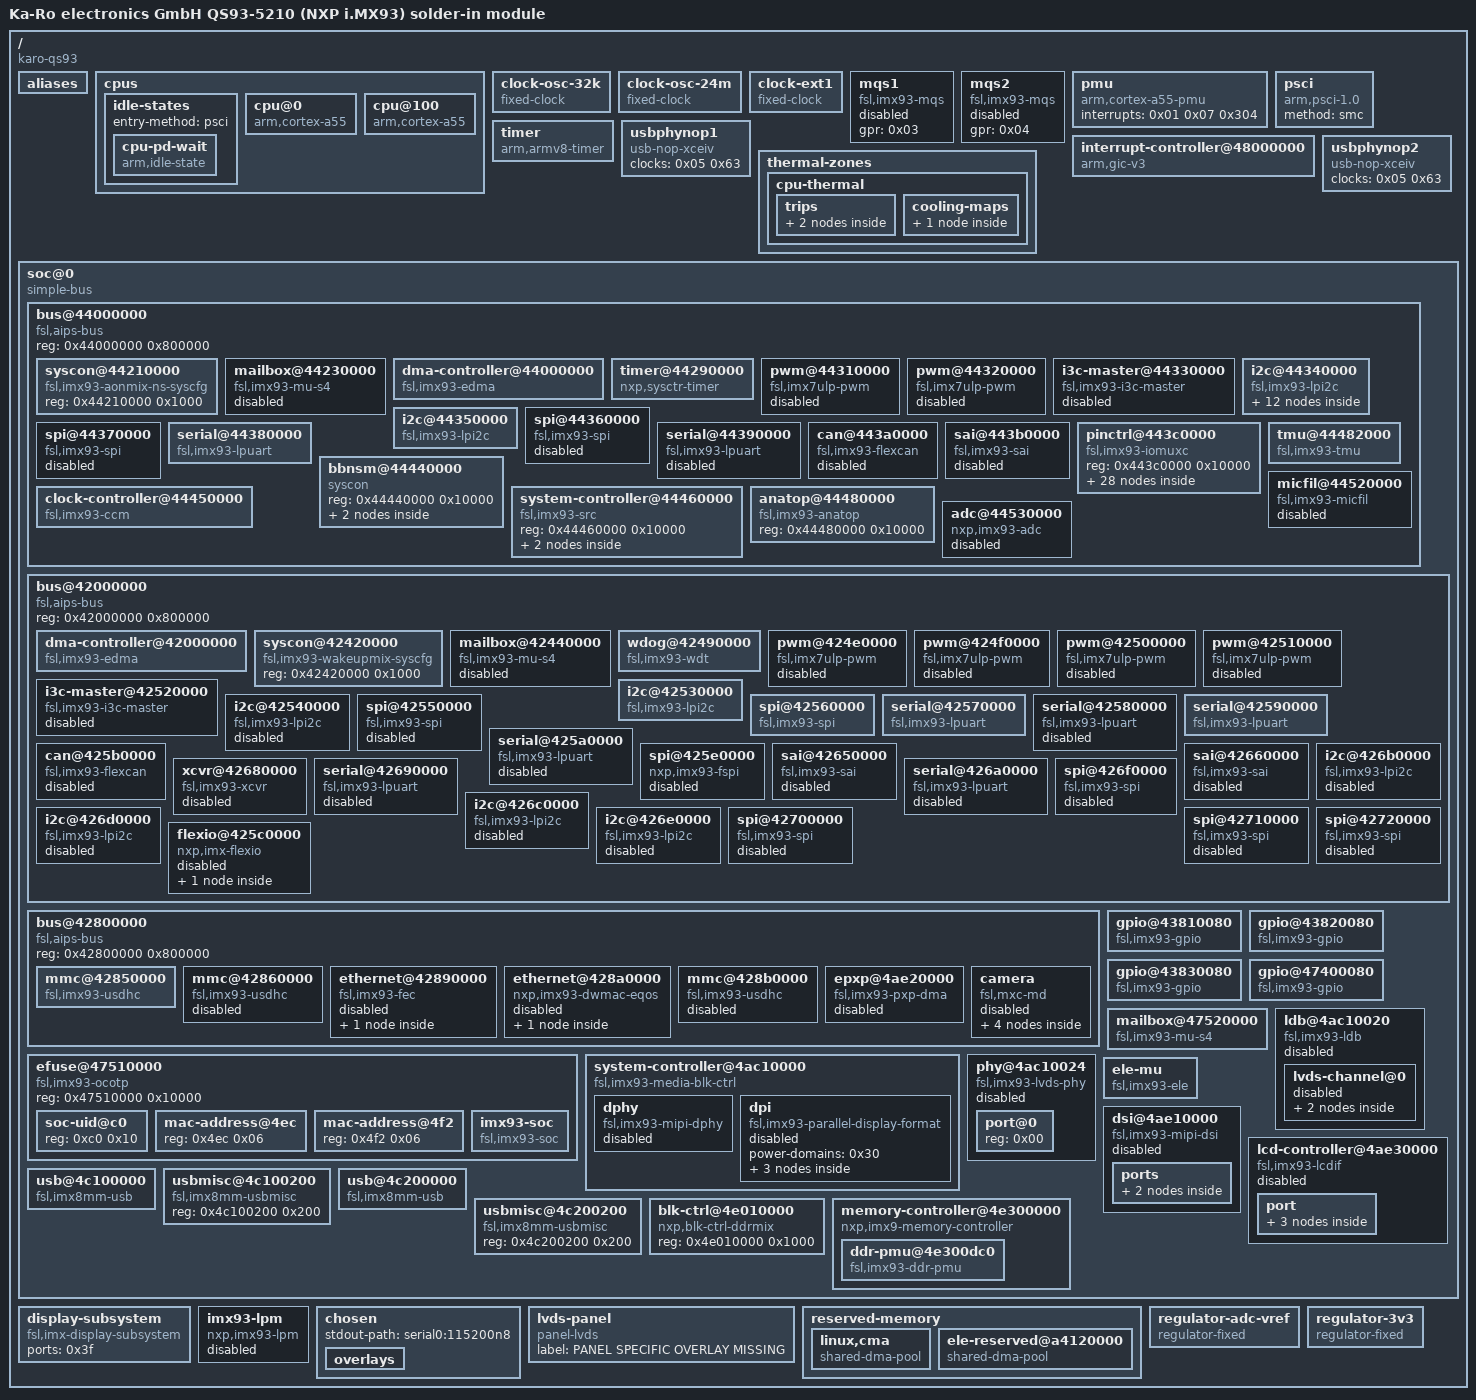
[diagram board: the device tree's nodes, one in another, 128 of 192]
/dts-v1/;

/ {
	interrupt-parent = <0x01>;
	#address-cells = <0x02>;
	#size-cells = <0x02>;
	model = "Ka-Ro electronics GmbH QS93-5210 (NXP i.MX93) solder-in module";
	compatible = "karo-qs93\0fsl,imx93";

	aliases {
		gpio0 = "/soc@0/gpio@47400080";
		gpio1 = "/soc@0/gpio@43810080";
		gpio2 = "/soc@0/gpio@43820080";
		gpio3 = "/soc@0/gpio@43830080";
		i2c0 = "/soc@0/bus@44000000/i2c@44340000";
		i2c1 = "/soc@0/bus@44000000/i2c@44350000";
		i2c2 = "/soc@0/bus@42000000/i2c@42530000";
		i2c3 = "/soc@0/bus@42000000/i2c@426b0000";
		i2c4 = "/soc@0/bus@42000000/i2c@42540000";
		i2c5 = "/soc@0/bus@42000000/i2c@426d0000";
		i2c6 = "/soc@0/bus@42000000/i2c@426e0000";
		i2c7 = "/soc@0/bus@42000000/i2c@426c0000";
		ethernet0 = "/soc@0/bus@42800000/ethernet@428a0000";
		ethernet1 = "/soc@0/bus@42800000/ethernet@42890000";
		mmc0 = "/soc@0/bus@42800000/mmc@42850000";
		mmc1 = "/soc@0/bus@42800000/mmc@428b0000";
		mmc2 = "/soc@0/bus@42800000/mmc@42860000";
		serial0 = "/soc@0/bus@44000000/serial@44380000";
		serial1 = "/soc@0/bus@42000000/serial@42570000";
		serial2 = "/soc@0/bus@42000000/serial@42590000";
		serial3 = "/soc@0/bus@42000000/serial@42580000";
		serial4 = "/soc@0/bus@44000000/serial@44390000";
		serial5 = "/soc@0/bus@42000000/serial@425a0000";
		serial6 = "/soc@0/bus@42000000/serial@42690000";
		serial7 = "/soc@0/bus@42000000/serial@426a0000";
		isi0 = "/soc@0/bus@42800000/camera/isi@4ae40000";
		csi0 = "/soc@0/bus@42800000/camera/csi@4ae00000";
		rtc0 = "/soc@0/bus@44000000/bbnsm@44440000/rtc";
		spi0 = "/soc@0/bus@42000000/spi@42560000";
		spi1 = "/soc@0/bus@42000000/spi@42550000";
		spi2 = "/soc@0/bus@44000000/spi@44360000";
		spi3 = "/soc@0/bus@42000000/spi@42700000";
		spi4 = "/soc@0/bus@42000000/spi@426f0000";
		spi5 = "/soc@0/bus@44000000/spi@44370000";
		usb-host = "/soc@0/usb@4c200000";
		usbotg = "/soc@0/usb@4c100000";
	};

	cpus {
		#address-cells = <0x01>;
		#size-cells = <0x00>;

		idle-states {
			entry-method = "psci";

			cpu-pd-wait {
				compatible = "arm,idle-state";
				arm,psci-suspend-param = <0x10033>;
				local-timer-stop;
				entry-latency-us = <0x2710>;
				exit-latency-us = <0x1b58>;
				min-residency-us = <0x6978>;
				wakeup-latency-us = <0x3a98>;
				phandle = <0x02>;
			};
		};

		cpu@0 {
			device_type = "cpu";
			compatible = "arm,cortex-a55";
			reg = <0x00>;
			enable-method = "psci";
			#cooling-cells = <0x02>;
			cpu-idle-states = <0x02>;
			phandle = <0x08>;
		};

		cpu@100 {
			device_type = "cpu";
			compatible = "arm,cortex-a55";
			reg = <0x100>;
			enable-method = "psci";
			#cooling-cells = <0x02>;
			cpu-idle-states = <0x02>;
			phandle = <0x09>;
		};
	};

	clock-osc-32k {
		compatible = "fixed-clock";
		#clock-cells = <0x00>;
		clock-frequency = <0x8000>;
		clock-output-names = "osc_32k";
		phandle = <0x14>;
	};

	clock-osc-24m {
		compatible = "fixed-clock";
		#clock-cells = <0x00>;
		clock-frequency = <0x16e3600>;
		clock-output-names = "osc_24m";
		phandle = <0x0a>;
	};

	clock-ext1 {
		compatible = "fixed-clock";
		#clock-cells = <0x00>;
		clock-frequency = <0x7ed6b40>;
		clock-output-names = "clk_ext1";
		phandle = <0x15>;
	};

	mqs1 {
		compatible = "fsl,imx93-mqs";
		gpr = <0x03>;
		status = "disabled";
		phandle = <0x42>;
	};

	mqs2 {
		compatible = "fsl,imx93-mqs";
		gpr = <0x04>;
		status = "disabled";
		phandle = <0x43>;
	};

	pmu {
		compatible = "arm,cortex-a55-pmu";
		interrupts = <0x01 0x07 0x304>;
	};

	psci {
		compatible = "arm,psci-1.0";
		method = "smc";
	};

	timer {
		compatible = "arm,armv8-timer";
		interrupts = <0x01 0x0d 0x3f08 0x01 0x0e 0x3f08 0x01 0x0b 0x3f08 0x01 0x0a 0x3f08>;
		clock-frequency = <0x16e3600>;
		arm,no-tick-in-suspend;
		interrupt-parent = <0x01>;
	};

	interrupt-controller@48000000 {
		compatible = "arm,gic-v3";
		reg = <0x00 0x48000000 0x00 0x10000 0x00 0x48040000 0x00 0xc0000>;
		#interrupt-cells = <0x03>;
		interrupt-controller;
		interrupts = <0x01 0x09 0x04>;
		interrupt-parent = <0x01>;
		phandle = <0x01>;
	};

	usbphynop1 {
		compatible = "usb-nop-xceiv";
		clocks = <0x05 0x63>;
		clock-names = "main_clk";
		phandle = <0x3b>;
	};

	usbphynop2 {
		compatible = "usb-nop-xceiv";
		clocks = <0x05 0x63>;
		clock-names = "main_clk";
		phandle = <0x3d>;
	};

	thermal-zones {

		cpu-thermal {
			polling-delay-passive = <0xfa>;
			polling-delay = <0x7d0>;
			thermal-sensors = <0x06 0x00>;

			trips {

				cpu-alert {
					temperature = <0x13880>;
					hysteresis = <0x7d0>;
					type = "passive";
					phandle = <0x07>;
				};

				cpu-crit {
					temperature = <0x15f90>;
					hysteresis = <0x7d0>;
					type = "critical";
					phandle = <0x44>;
				};
			};

			cooling-maps {

				map0 {
					trip = <0x07>;
					cooling-device = <0x08 0xffffffff 0xffffffff 0x09 0xffffffff 0xffffffff>;
				};
			};
		};
	};

	soc@0 {
		compatible = "simple-bus";
		#address-cells = <0x01>;
		#size-cells = <0x01>;
		ranges = <0x00 0x00 0x00 0x80000000 0x28000000 0x00 0x28000000 0x10000000>;

		bus@44000000 {
			compatible = "fsl,aips-bus\0simple-bus";
			reg = <0x44000000 0x800000>;
			#address-cells = <0x01>;
			#size-cells = <0x01>;
			ranges;
			phandle = <0x45>;

			syscon@44210000 {
				compatible = "fsl,imx93-aonmix-ns-syscfg\0syscon";
				reg = <0x44210000 0x1000>;
				phandle = <0x03>;
			};

			mailbox@44230000 {
				compatible = "fsl,imx93-mu-s4";
				reg = <0x44230000 0x10000>;
				interrupts = <0x00 0x16 0x04>;
				clocks = <0x05 0xc2>;
				#mbox-cells = <0x02>;
				status = "disabled";
				phandle = <0x46>;
			};

			dma-controller@44000000 {
				compatible = "fsl,imx93-edma";
				reg = <0x44000000 0x10000 0x44010000 0x10000 0x44020000 0x10000 0x44030000 0x10000 0x44040000 0x10000 0x44050000 0x10000 0x44060000 0x10000 0x44070000 0x10000 0x44080000 0x10000 0x44090000 0x10000 0x440a0000 0x10000 0x440b0000 0x10000 0x440c0000 0x10000 0x440d0000 0x10000 0x440e0000 0x10000 0x440f0000 0x10000 0x44100000 0x10000 0x44110000 0x10000 0x44120000 0x10000 0x44130000 0x10000 0x44140000 0x10000 0x44150000 0x10000 0x44160000 0x10000 0x44170000 0x10000 0x44180000 0x10000 0x44190000 0x10000 0x441a0000 0x10000 0x441b0000 0x10000 0x441c0000 0x10000 0x441d0000 0x10000 0x441e0000 0x10000 0x441f0000 0x10000>;
				#dma-cells = <0x03>;
				dma-channels = <0x1f>;
				interrupts = <0x00 0x5f 0x04 0x00 0x60 0x04 0x00 0x61 0x04 0x00 0x62 0x04 0x00 0x63 0x04 0x00 0x64 0x04 0x00 0x65 0x04 0x00 0x66 0x04 0x00 0x67 0x04 0x00 0x68 0x04 0x00 0x69 0x04 0x00 0x6a 0x04 0x00 0x6b 0x04 0x00 0x6c 0x04 0x00 0x6d 0x04 0x00 0x6e 0x04 0x00 0x6f 0x04 0x00 0x70 0x04 0x00 0x71 0x04 0x00 0x72 0x04 0x00 0x73 0x04 0x00 0x74 0x04 0x00 0x75 0x04 0x00 0x76 0x04 0x00 0x77 0x04 0x00 0x78 0x04 0x00 0x79 0x04 0x00 0x7a 0x04 0x00 0x7b 0x04 0x00 0x7c 0x04 0x00 0x7d 0x04 0x00 0x5e 0x04>;
				interrupt-names = "edma1-chan0-tx\0edma1-chan1-tx\0edma1-chan2-tx\0edma1-chan3-tx\0edma1-chan4-tx\0edma1-chan5-tx\0edma1-chan6-tx\0edma1-chan7-tx\0edma1-chan8-tx\0edma1-chan9-tx\0edma1-chan10-tx\0edma1-chan11-tx\0edma1-chan12-tx\0edma1-chan13-tx\0edma1-chan14-tx\0edma1-chan15-tx\0edma1-chan16-tx\0edma1-chan17-tx\0edma1-chan18-tx\0edma1-chan19-tx\0edma1-chan20-tx\0edma1-chan21-tx\0edma1-chan22-tx\0edma1-chan23-tx\0edma1-chan24-tx\0edma1-chan25-tx\0edma1-chan26-tx\0edma1-chan27-tx\0edma1-chan28-tx\0edma1-chan29-tx\0edma1-chan30-tx\0edma1-err";
				clocks = <0x05 0x71>;
				clock-names = "edma";
				status = "okay";
				phandle = <0x0b>;
			};

			timer@44290000 {
				compatible = "nxp,sysctr-timer";
				reg = <0x44290000 0x30000>;
				interrupts = <0x00 0x4a 0x04>;
				clocks = <0x0a>;
				clock-names = "per";
				nxp,no-divider;
				phandle = <0x47>;
			};

			pwm@44310000 {
				compatible = "fsl,imx7ulp-pwm";
				reg = <0x44310000 0x1000>;
				clocks = <0x05 0x7e>;
				#pwm-cells = <0x03>;
				status = "disabled";
				phandle = <0x48>;
			};

			pwm@44320000 {
				compatible = "fsl,imx7ulp-pwm";
				reg = <0x44320000 0x1000>;
				clocks = <0x05 0x7f>;
				assigned-clocks = <0x05 0x1b>;
				assigned-clock-parents = <0x05 0x01>;
				assigned-clock-rates = <0x16e3600>;
				#pwm-cells = <0x03>;
				status = "disabled";
				phandle = <0x49>;
			};

			i3c-master@44330000 {
				#address-cells = <0x03>;
				#size-cells = <0x00>;
				compatible = "fsl,imx93-i3c-master\0silvaco,i3c-master";
				reg = <0x44330000 0x10000>;
				interrupts = <0x00 0x0c 0x04>;
				clocks = <0x05 0x10 0x05 0x9e 0x05 0x00>;
				clock-names = "pclk\0fast_clk\0slow_clk";
				status = "disabled";
				phandle = <0x4a>;
			};

			i2c@44340000 {
				compatible = "fsl,imx93-lpi2c\0fsl,imx7ulp-lpi2c";
				reg = <0x44340000 0x10000>;
				#address-cells = <0x01>;
				#size-cells = <0x00>;
				interrupts = <0x00 0x0d 0x04>;
				clocks = <0x05 0x8e 0x05 0x10>;
				clock-names = "per\0ipg";
				dmas = <0x0b 0x07 0x00 0x00 0x0b 0x08 0x00 0x01>;
				dma-names = "tx\0rx";
				status = "okay";
				clock-frequency = <0x61a80>;
				pinctrl-names = "default\0gpio";
				pinctrl-0 = <0x0c>;
				pinctrl-1 = <0x0d>;
				scl-gpios = <0x0e 0x00 0x06>;
				sda-gpios = <0x0e 0x01 0x06>;
				phandle = <0x4b>;

				pmic@25 {
					compatible = "nxp,pca9451a";
					reg = <0x25>;
					pinctrl-names = "default";
					pinctrl-0 = <0x0f>;
					interrupt-parent = <0x0e>;
					interrupts = <0x0a 0x08>;
					phandle = <0x4c>;

					regulators {

						BUCK1 {
							regulator-name = "BUCK1";
							regulator-min-microvolt = <0x927c0>;
							regulator-max-microvolt = <0x2160ec>;
							regulator-boot-on;
							regulator-always-on;
							regulator-ramp-delay = <0xc35>;
							phandle = <0x4d>;
						};

						BUCK2 {
							regulator-name = "BUCK2";
							regulator-min-microvolt = <0x927c0>;
							regulator-max-microvolt = <0x2160ec>;
							regulator-boot-on;
							regulator-always-on;
							regulator-ramp-delay = <0xc35>;
							phandle = <0x4e>;
						};

						BUCK4 {
							regulator-name = "BUCK4";
							regulator-min-microvolt = <0x927c0>;
							regulator-max-microvolt = <0x33e140>;
							regulator-boot-on;
							regulator-always-on;
							phandle = <0x2a>;
						};

						BUCK5 {
							regulator-name = "BUCK5";
							regulator-min-microvolt = <0x927c0>;
							regulator-max-microvolt = <0x33e140>;
							regulator-boot-on;
							regulator-always-on;
							phandle = <0x41>;
						};

						BUCK6 {
							regulator-name = "BUCK6";
							regulator-min-microvolt = <0x927c0>;
							regulator-max-microvolt = <0x33e140>;
							regulator-boot-on;
							regulator-always-on;
							phandle = <0x4f>;
						};

						LDO1 {
							regulator-name = "LDO1";
							regulator-min-microvolt = <0x186a00>;
							regulator-max-microvolt = <0x325aa0>;
							regulator-boot-on;
							regulator-always-on;
							phandle = <0x50>;
						};

						LDO2 {
							regulator-name = "LDO2";
							regulator-min-microvolt = <0xc3500>;
							regulator-max-microvolt = <0x118c30>;
							regulator-boot-on;
							regulator-always-on;
							phandle = <0x51>;
						};

						LDO3 {
							regulator-name = "LDO3";
							regulator-min-microvolt = <0xc3500>;
							regulator-max-microvolt = <0x325aa0>;
							regulator-boot-on;
							regulator-always-on;
							phandle = <0x52>;
						};

						LDO4 {
							regulator-name = "LDO4";
							regulator-min-microvolt = <0xc3500>;
							regulator-max-microvolt = <0x325aa0>;
							regulator-boot-on;
							regulator-always-on;
							phandle = <0x53>;
						};

						LDO5 {
							regulator-name = "LDO5";
							regulator-min-microvolt = <0x1b7740>;
							regulator-max-microvolt = <0x325aa0>;
							regulator-boot-on;
							regulator-always-on;
							phandle = <0x54>;
						};
					};
				};
			};

			i2c@44350000 {
				compatible = "fsl,imx93-lpi2c\0fsl,imx7ulp-lpi2c";
				reg = <0x44350000 0x10000>;
				#address-cells = <0x01>;
				#size-cells = <0x00>;
				interrupts = <0x00 0x0e 0x04>;
				clocks = <0x05 0x8f 0x05 0x10>;
				clock-names = "per\0ipg";
				dmas = <0x0b 0x09 0x00 0x00 0x0b 0x0a 0x00 0x01>;
				dma-names = "tx\0rx";
				status = "okay";
				clock-frequency = <0x61a80>;
				pinctrl-names = "default\0gpio";
				pinctrl-0 = <0x10>;
				pinctrl-1 = <0x11>;
				scl-gpios = <0x0e 0x02 0x06>;
				sda-gpios = <0x0e 0x03 0x06>;
				phandle = <0x55>;
			};

			spi@44360000 {
				#address-cells = <0x01>;
				#size-cells = <0x00>;
				compatible = "fsl,imx93-spi\0fsl,imx7ulp-spi";
				reg = <0x44360000 0x10000>;
				interrupts = <0x00 0x10 0x04>;
				clocks = <0x05 0x96 0x05 0x10>;
				clock-names = "per\0ipg";
				dmas = <0x0b 0x0b 0x00 0x00 0x0b 0x0c 0x00 0x01>;
				dma-names = "tx\0rx";
				status = "disabled";
				phandle = <0x56>;
			};

			spi@44370000 {
				#address-cells = <0x01>;
				#size-cells = <0x00>;
				compatible = "fsl,imx93-spi\0fsl,imx7ulp-spi";
				reg = <0x44370000 0x10000>;
				interrupts = <0x00 0x11 0x04>;
				clocks = <0x05 0x97 0x05 0x10>;
				clock-names = "per\0ipg";
				dmas = <0x0b 0x0d 0x00 0x00 0x0b 0x0e 0x00 0x01>;
				dma-names = "tx\0rx";
				status = "disabled";
				phandle = <0x57>;
			};

			serial@44380000 {
				compatible = "fsl,imx93-lpuart\0fsl,imx8ulp-lpuart";
				reg = <0x44380000 0x1000>;
				interrupts = <0x00 0x13 0x04>;
				clocks = <0x05 0x86>;
				clock-names = "ipg";
				status = "okay";
				pinctrl-names = "default";
				pinctrl-0 = <0x12>;
				phandle = <0x58>;
			};

			serial@44390000 {
				compatible = "fsl,imx93-lpuart\0fsl,imx8ulp-lpuart";
				reg = <0x44390000 0x1000>;
				interrupts = <0x00 0x14 0x04>;
				clocks = <0x05 0x87>;
				clock-names = "ipg";
				dmas = <0x0b 0x12 0x00 0x00 0x0b 0x13 0x00 0x01>;
				dma-names = "tx\0rx";
				status = "disabled";
				phandle = <0x59>;
			};

			can@443a0000 {
				compatible = "fsl,imx93-flexcan";
				reg = <0x443a0000 0x10000>;
				interrupts = <0x00 0x08 0x04>;
				clocks = <0x05 0x10 0x05 0x84>;
				clock-names = "ipg\0per";
				assigned-clocks = <0x05 0x21>;
				assigned-clock-parents = <0x05 0x06>;
				assigned-clock-rates = <0x2625a00>;
				fsl,clk-source = [00];
				fsl,stop-mode = <0x03 0x14 0x00>;
				status = "disabled";
				phandle = <0x5a>;
			};

			sai@443b0000 {
				compatible = "fsl,imx93-sai";
				reg = <0x443b0000 0x10000>;
				interrupts = <0x00 0x2d 0x04>;
				clocks = <0x05 0xbe 0x05 0x00 0x05 0xa3 0x05 0x00 0x05 0x00>;
				clock-names = "bus\0mclk0\0mclk1\0mclk2\0mclk3";
				dmas = <0x0b 0x16 0x00 0x01 0x0b 0x15 0x00 0x00>;
				dma-names = "rx\0tx";
				status = "disabled";
				phandle = <0x5b>;
			};

			pinctrl@443c0000 {
				compatible = "fsl,imx93-iomuxc";
				reg = <0x443c0000 0x10000>;
				status = "okay";
				pinctrl-names = "default";
				phandle = <0x2e>;

				flexcan2grp {
					fsl,pins = <0x74 0x224 0x00 0x02 0x00 0x139e 0x7c 0x22c 0x364 0x02 0x01 0x139e>;
					phandle = <0x5c>;
				};

				flexspigrp {
					fsl,pins = <0x13c 0x2ec 0x00 0x01 0x00 0x3fe 0x11c 0x2cc 0x00 0x01 0x00 0x3fe 0x138 0x2e8 0x00 0x01 0x00 0x3fe 0x130 0x2e0 0x00 0x01 0x00 0x3fe 0x140 0x2f0 0x00 0x01 0x00 0x3fe 0x144 0x2f4 0x00 0x01 0x00 0x3fe 0x148 0x2f8 0x00 0x01 0x00 0x3fe 0x14c 0x2fc 0x00 0x01 0x00 0x3fe 0x120 0x2d0 0x00 0x01 0x00 0x3fe 0x124 0x2d4 0x00 0x01 0x00 0x3fe 0x128 0x2d8 0x00 0x01 0x00 0x3fe 0x12c 0x2dc 0x00 0x01 0x00 0x3fe>;
					phandle = <0x5d>;
				};

				lpi2c1grp {
					fsl,pins = <0x170 0x320 0x00 0x10 0x00 0x40001a1e 0x174 0x324 0x00 0x10 0x00 0x40001a1e>;
					phandle = <0x0c>;
				};

				lpi2c1-gpiogrp {
					fsl,pins = <0x170 0x320 0x00 0x05 0x00 0x40001a1e 0x174 0x324 0x00 0x05 0x00 0x40001a1e>;
					phandle = <0x0d>;
				};

				lpi2c2grp {
					fsl,pins = <0x178 0x328 0x00 0x10 0x00 0x40001a1e 0x17c 0x32c 0x00 0x10 0x00 0x40001a1e>;
					phandle = <0x10>;
				};

				lpi2c2-gpiogrp {
					fsl,pins = <0x178 0x328 0x00 0x05 0x00 0x40001a1e 0x17c 0x32c 0x00 0x05 0x00 0x40001a1e>;
					phandle = <0x11>;
				};

				lpi2c3grp {
					fsl,pins = <0x80 0x230 0x3e4 0x11 0x01 0x40001a1e 0x84 0x234 0x3e0 0x11 0x01 0x40001a1e>;
					phandle = <0x17>;
				};

				lpi2c3-gpiogrp {
					fsl,pins = <0x80 0x230 0x00 0x00 0x00 0x40001a1e 0x84 0x234 0x00 0x00 0x00 0x40001a1e>;
					phandle = <0x18>;
				};

				lpi2c4grp {
					fsl,pins = <0x18 0x1c8 0x00 0x11 0x00 0x40001a1e 0x1c 0x1cc 0x00 0x11 0x00 0x40001a1e>;
					phandle = <0x1a>;
				};

				lpi2c4-gpiogrp {
					fsl,pins = <0x18 0x1c8 0x00 0x00 0x00 0x40001a1e 0x1c 0x1cc 0x00 0x00 0x00 0x40001a1e>;
					phandle = <0x1b>;
				};

				lpi2c5grp {
					fsl,pins = <0x68 0x218 0x3ec 0x16 0x01 0x40001a1e 0x6c 0x21c 0x3e8 0x16 0x01 0x40001a1e>;
					phandle = <0x23>;
				};

				lpi2c5-gpiogrp {
					fsl,pins = <0x68 0x218 0x00 0x00 0x00 0x40001a1e 0x6c 0x21c 0x00 0x00 0x00 0x40001a1e>;
					phandle = <0x24>;
				};

				lpi2c7grp {
					fsl,pins = <0x30 0x1e0 0x3fc 0x16 0x01 0x40001a1e 0x34 0x1e4 0x3f8 0x16 0x01 0x40001a1e>;
					phandle = <0x25>;
				};

				lpi2c7-gpiogrp {
					fsl,pins = <0x30 0x1e0 0x00 0x00 0x00 0x40001a1e 0x34 0x1e4 0x00 0x00 0x00 0x40001a1e>;
					phandle = <0x26>;
				};

				lpi2c8grp {
					fsl,pins = <0x38 0x1e8 0x404 0x16 0x00 0x40001a1e 0x3c 0x1ec 0x400 0x16 0x00 0x40001a1e>;
					phandle = <0x27>;
				};

				lpi2c8-gpiogrp {
					fsl,pins = <0x38 0x1e8 0x00 0x00 0x00 0x40001a1e 0x3c 0x1ec 0x00 0x00 0x00 0x40001a1e>;
					phandle = <0x28>;
				};

				lpspi3-grp {
					fsl,pins = <0x34 0x1e4 0x00 0x01 0x00 0x131e 0x38 0x1e8 0x00 0x01 0x00 0x11e 0x3c 0x1ec 0x00 0x01 0x00 0x11e>;
					phandle = <0x1c>;
				};

				lpspi3-csgrp {
					fsl,pins = <0x30 0x1e0 0x00 0x00 0x00 0x4000121e>;
					phandle = <0x1d>;
				};

				lpspi4-grp {
					fsl,pins = <0x5c 0x20c 0x00 0x05 0x00 0x131e 0x60 0x210 0x00 0x05 0x00 0x11e 0x64 0x214 0x00 0x05 0x00 0x11e>;
					phandle = <0x1e>;
				};

				lpspi4-csgrp {
					fsl,pins = <0x58 0x208 0x00 0x00 0x00 0x4000121e>;
					phandle = <0x1f>;
				};

				pmic-intgrp {
					fsl,pins = <0x198 0x348 0x00 0x05 0x00 0x00>;
					phandle = <0x0f>;
				};

				uart1grp {
					fsl,pins = <0x184 0x334 0x00 0x00 0x00 0x1e 0x180 0x330 0x00 0x00 0x00 0x400>;
					phandle = <0x12>;
				};

				uart3grp {
					fsl,pins = <0x48 0x1f8 0x41c 0x01 0x00 0x1e 0x4c 0x1fc 0x418 0x01 0x00 0x400>;
					phandle = <0x20>;
				};

				uart5grp {
					fsl,pins = <0x10 0x1c0 0x434 0x05 0x01 0x1e 0x14 0x1c4 0x430 0x05 0x01 0x400>;
					phandle = <0x21>;
				};

				uart5-rtsctsgrp {
					fsl,pins = <0x18 0x1c8 0x42c 0x05 0x01 0x1e 0x1c 0x1cc 0x00 0x05 0x00 0x400>;
					phandle = <0x22>;
				};

				usdhc1grp {
					fsl,pins = <0x108 0x2b8 0x00 0x00 0x00 0x1fe 0x10c 0x2bc 0x00 0x00 0x00 0x13fe 0x110 0x2c0 0x00 0x00 0x00 0x13fe 0x114 0x2c4 0x00 0x00 0x00 0x13fe 0x118 0x2c8 0x00 0x00 0x00 0x13fe 0x11c 0x2cc 0x00 0x00 0x00 0x13fe 0x120 0x2d0 0x00 0x00 0x00 0x13fe 0x124 0x2d4 0x00 0x00 0x00 0x13fe 0x128 0x2d8 0x00 0x00 0x00 0x13fe 0x12c 0x2dc 0x00 0x00 0x00 0x13fe 0x130 0x2e0 0x00 0x00 0x00 0x1fe>;
					phandle = <0x29>;
				};

				usdhc3grp {
					fsl,pins = <0x154 0x304 0x00 0x00 0x00 0x1fe 0x158 0x308 0x00 0x00 0x00 0x13fe 0x15c 0x30c 0x00 0x00 0x00 0x13fe 0x160 0x310 0x00 0x00 0x00 0x13fe 0x164 0x314 0x00 0x00 0x00 0x13fe 0x168 0x318 0x00 0x00 0x00 0x13fe>;
					phandle = <0x2c>;
				};

				usdhc3-cdgrp {
					fsl,pins = <0x168 0x318 0x00 0x05 0x00 0x200>;
					phandle = <0x5e>;
				};
			};

			bbnsm@44440000 {
				compatible = "syscon\0simple-mfd";
				reg = <0x44440000 0x10000>;
				phandle = <0x13>;

				rtc {
					compatible = "nxp,bbnsm-rtc";
					regmap = <0x13>;
					interrupts = <0x00 0x49 0x04>;
					phandle = <0x5f>;
				};

				pwrkey {
					compatible = "nxp,bbnsm-pwrkey";
					regmap = <0x13>;
					interrupts = <0x00 0x49 0x04>;
					phandle = <0x60>;
				};
			};

			clock-controller@44450000 {
				compatible = "fsl,imx93-ccm";
				reg = <0x44450000 0x10000>;
				#clock-cells = <0x01>;
				clocks = <0x14 0x0a 0x15>;
				clock-names = "osc_32k\0osc_24m\0clk_ext1";
				assigned-clocks = <0x05 0x09 0x05 0x0d>;
				assigned-clock-parents = <0x00 0x05 0x03>;
				assigned-clock-rates = <0x17700000 0x1dcd6500>;
				status = "okay";
				phandle = <0x05>;
			};

			system-controller@44460000 {
				compatible = "fsl,imx93-src\0syscon";
				reg = <0x44460000 0x10000>;
				#address-cells = <0x01>;
				#size-cells = <0x01>;
				ranges;
				phandle = <0x61>;

				power-domain@44462400 {
					compatible = "fsl,imx93-src-slice";
					reg = <0x44462400 0x400 0x44465800 0x400>;
					#power-domain-cells = <0x00>;
					clocks = <0x05 0xac 0x05 0x4e>;
					phandle = <0x30>;
				};

				power-domain@44461800 {
					compatible = "fsl,imx93-src-slice";
					reg = <0x44461800 0x400 0x44464800 0x400>;
					#power-domain-cells = <0x00>;
					clocks = <0x05 0x4b 0x05 0x4c>;
					phandle = <0x62>;
				};
			};

			anatop@44480000 {
				compatible = "fsl,imx93-anatop\0syscon";
				reg = <0x44480000 0x10000>;
				phandle = <0x63>;
			};

			tmu@44482000 {
				compatible = "fsl,imx93-tmu";
				reg = <0x44482000 0x1000>;
				clocks = <0x05 0xbb>;
				little-endian;
				fsl,tmu-calibration = <0x0e 0x800000da 0x29 0x800000e9 0x56 0x80000102 0xa2 0x8000012a 0x116 0x80000166 0x195 0x800001a7 0x1b2 0x800001b6>;
				#thermal-sensor-cells = <0x01>;
				phandle = <0x06>;
			};

			micfil@44520000 {
				compatible = "fsl,imx93-micfil";
				reg = <0x44520000 0x10000>;
				interrupts = <0x00 0xca 0x04 0x00 0xc9 0x04 0x00 0xc8 0x04 0x00 0xc7 0x04>;
				clocks = <0x05 0xc9 0x05 0xb0 0x05 0x09 0x05 0x00>;
				clock-names = "ipg_clk\0ipg_clk_app\0pll8k\0clkext3";
				dmas = <0x0b 0x1d 0x00 0x05>;
				dma-names = "rx";
				status = "disabled";
				phandle = <0x64>;
			};

			adc@44530000 {
				compatible = "nxp,imx93-adc";
				reg = <0x44530000 0x10000>;
				interrupts = <0x00 0xd9 0x04 0x00 0xda 0x04 0x00 0xdb 0x04 0x00 0x10c 0x04>;
				clocks = <0x05 0x67>;
				clock-names = "ipg";
				status = "disabled";
				phandle = <0x65>;
			};
		};

		bus@42000000 {
			compatible = "fsl,aips-bus\0simple-bus";
			reg = <0x42000000 0x800000>;
			#address-cells = <0x01>;
			#size-cells = <0x01>;
			ranges;
			phandle = <0x66>;

			dma-controller@42000000 {
				compatible = "fsl,imx93-edma";
				reg = <0x42000000 0x10000 0x42010000 0x8000 0x42018000 0x8000 0x42020000 0x8000 0x42028000 0x8000 0x42030000 0x8000 0x42038000 0x8000 0x42040000 0x8000 0x42048000 0x8000 0x42050000 0x8000 0x42058000 0x8000 0x42060000 0x8000 0x42068000 0x8000 0x42070000 0x8000 0x42078000 0x8000 0x42080000 0x8000 0x42088000 0x8000 0x42090000 0x8000 0x42098000 0x8000 0x420a0000 0x8000 0x420a8000 0x8000 0x420b0000 0x8000 0x420b8000 0x8000 0x420c0000 0x8000 0x420c8000 0x8000 0x420d0000 0x8000 0x420d8000 0x8000 0x420e0000 0x8000 0x420e8000 0x8000 0x420f0000 0x8000 0x420f8000 0x8000 0x42100000 0x8000 0x42108000 0x8000 0x42110000 0x8000 0x42118000 0x8000 0x42120000 0x8000 0x42128000 0x8000 0x42130000 0x8000 0x42138000 0x8000 0x42140000 0x8000 0x42148000 0x8000 0x42150000 0x8000 0x42158000 0x8000 0x42160000 0x8000 0x42168000 0x8000 0x42170000 0x8000 0x42178000 0x8000 0x42180000 0x8000 0x42188000 0x8000 0x42190000 0x8000 0x42198000 0x8000 0x421a0000 0x8000 0x421a8000 0x8000 0x421b0000 0x8000 0x421b8000 0x8000 0x421c0000 0x8000 0x421c8000 0x8000 0x421d0000 0x8000 0x421d8000 0x8000 0x421e0000 0x8000 0x421e8000 0x8000 0x421f0000 0x8000 0x421f8000 0x8000 0x42200000 0x8000 0x42208000 0x8000>;
				#dma-cells = <0x03>;
				shared-interrupt;
				dma-channels = <0x40>;
				interrupts = <0x00 0x80 0x04 0x00 0x80 0x04 0x00 0x81 0x04 0x00 0x81 0x04 0x00 0x82 0x04 0x00 0x82 0x04 0x00 0x83 0x04 0x00 0x83 0x04 0x00 0x84 0x04 0x00 0x84 0x04 0x00 0x85 0x04 0x00 0x85 0x04 0x00 0x86 0x04 0x00 0x86 0x04 0x00 0x87 0x04 0x00 0x87 0x04 0x00 0x88 0x04 0x00 0x88 0x04 0x00 0x89 0x04 0x00 0x89 0x04 0x00 0x8a 0x04 0x00 0x8a 0x04 0x00 0x8b 0x04 0x00 0x8b 0x04 0x00 0x8c 0x04 0x00 0x8c 0x04 0x00 0x8d 0x04 0x00 0x8d 0x04 0x00 0x8e 0x04 0x00 0x8e 0x04 0x00 0x8f 0x04 0x00 0x8f 0x04 0x00 0x90 0x04 0x00 0x90 0x04 0x00 0x91 0x04 0x00 0x91 0x04 0x00 0x92 0x04 0x00 0x92 0x04 0x00 0x93 0x04 0x00 0x93 0x04 0x00 0x94 0x04 0x00 0x94 0x04 0x00 0x95 0x04 0x00 0x95 0x04 0x00 0x96 0x04 0x00 0x96 0x04 0x00 0x97 0x04 0x00 0x97 0x04 0x00 0x98 0x04 0x00 0x98 0x04 0x00 0x99 0x04 0x00 0x99 0x04 0x00 0x9a 0x04 0x00 0x9a 0x04 0x00 0x9b 0x04 0x00 0x9b 0x04 0x00 0x9c 0x04 0x00 0x9c 0x04 0x00 0x9d 0x04 0x00 0x9d 0x04 0x00 0x9e 0x04 0x00 0x9e 0x04 0x00 0x9f 0x04 0x00 0x9f 0x04 0x00 0x7f 0x04>;
				interrupt-names = "edma2-chan0-tx\0edma2-chan1-tx\0edma2-chan2-tx\0edma2-chan3-tx\0edma2-chan4-tx\0edma2-chan5-tx\0edma2-chan6-tx\0edma2-chan7-tx\0edma2-chan8-tx\0edma2-chan9-tx\0edma2-chan10-tx\0edma2-chan11-tx\0edma2-chan12-tx\0edma2-chan13-tx\0edma2-chan14-tx\0edma2-chan15-tx\0edma2-chan16-tx\0edma2-chan17-tx\0edma2-chan18-tx\0edma2-chan19-tx\0edma2-chan20-tx\0edma2-chan21-tx\0edma2-chan22-tx\0edma2-chan23-tx\0edma2-chan24-tx\0edma2-chan25-tx\0edma2-chan26-tx\0edma2-chan27-tx\0edma2-chan28-tx\0edma2-chan29-tx\0edma2-chan30-tx\0edma2-chan31-tx\0edma2-chan32-tx\0edma2-chan33-tx\0edma2-chan34-tx\0edma2-chan35-tx\0edma2-chan36-tx\0edma2-chan37-tx\0edma2-chan38-tx\0edma2-chan39-tx\0edma2-chan40-tx\0edma2-chan41-tx\0edma2-chan42-tx\0edma2-chan43-tx\0edma2-chan44-tx\0edma2-chan45-tx\0edma2-chan46-tx\0edma2-chan47-tx\0edma2-chan48-tx\0edma2-chan49-tx\0edma2-chan50-tx\0edma2-chan51-tx\0edma2-chan52-tx\0edma2-chan53-tx\0edma2-chan54-tx\0edma2-chan55-tx\0edma2-chan56-tx\0edma2-chan57-tx\0edma2-chan58-tx\0edma2-chan59-tx\0edma2-chan60-tx\0edma2-chan61-tx\0edma2-chan62-tx\0edma2-chan63-tx\0edma2-err";
				clocks = <0x05 0x72>;
				clock-names = "edma";
				fsl,edma-axi;
				status = "okay";
				phandle = <0x16>;
			};

			syscon@42420000 {
				compatible = "fsl,imx93-wakeupmix-syscfg\0syscon";
				reg = <0x42420000 0x1000>;
				phandle = <0x04>;
			};

			mailbox@42440000 {
				compatible = "fsl,imx93-mu-s4";
				reg = <0x42440000 0x10000>;
				interrupts = <0x00 0x18 0x04>;
				clocks = <0x05 0xc4>;
				#mbox-cells = <0x02>;
				status = "disabled";
				phandle = <0x67>;
			};

			wdog@42490000 {
				compatible = "fsl,imx93-wdt";
				reg = <0x42490000 0x10000>;
				interrupts = <0x00 0x4f 0x04>;
				clocks = <0x05 0x6a>;
				timeout-sec = <0x28>;
				status = "okay";
				phandle = <0x68>;
			};

			pwm@424e0000 {
				compatible = "fsl,imx7ulp-pwm";
				reg = <0x424e0000 0x1000>;
				clocks = <0x05 0x80>;
				#pwm-cells = <0x03>;
				status = "disabled";
				phandle = <0x69>;
			};

			pwm@424f0000 {
				compatible = "fsl,imx7ulp-pwm";
				reg = <0x424f0000 0x1000>;
				clocks = <0x05 0x81>;
				assigned-clocks = <0x05 0x1d>;
				assigned-clock-parents = <0x05 0x01>;
				assigned-clock-rates = <0x16e3600>;
				#pwm-cells = <0x03>;
				status = "disabled";
				phandle = <0x6a>;
			};

			pwm@42500000 {
				compatible = "fsl,imx7ulp-pwm";
				reg = <0x42500000 0x1000>;
				clocks = <0x05 0x82>;
				assigned-clocks = <0x05 0x1e>;
				assigned-clock-parents = <0x05 0x01>;
				assigned-clock-rates = <0x16e3600>;
				#pwm-cells = <0x03>;
				status = "disabled";
				phandle = <0x6b>;
			};

			pwm@42510000 {
				compatible = "fsl,imx7ulp-pwm";
				reg = <0x42510000 0x1000>;
				clocks = <0x05 0x83>;
				assigned-clocks = <0x05 0x1f>;
				assigned-clock-parents = <0x05 0x01>;
				assigned-clock-rates = <0x16e3600>;
				#pwm-cells = <0x03>;
				status = "disabled";
				phandle = <0x6c>;
			};

			i3c-master@42520000 {
				#address-cells = <0x03>;
				#size-cells = <0x00>;
				compatible = "fsl,imx93-i3c-master\0silvaco,i3c-master";
				reg = <0x42520000 0x10000>;
				interrupts = <0x00 0x3d 0x04>;
				clocks = <0x05 0x0f 0x05 0x9f 0x05 0x00>;
				clock-names = "pclk\0fast_clk\0slow_clk";
				status = "disabled";
				phandle = <0x6d>;
			};

			i2c@42530000 {
				compatible = "fsl,imx93-lpi2c\0fsl,imx7ulp-lpi2c";
				reg = <0x42530000 0x10000>;
				#address-cells = <0x01>;
				#size-cells = <0x00>;
				interrupts = <0x00 0x3e 0x04>;
				clocks = <0x05 0x90 0x05 0x0f>;
				clock-names = "per\0ipg";
				dmas = <0x16 0x08 0x00 0x00 0x16 0x09 0x00 0x01>;
				dma-names = "tx\0rx";
				status = "okay";
				clock-frequency = <0x61a80>;
				pinctrl-names = "default\0gpio";
				pinctrl-0 = <0x17>;
				pinctrl-1 = <0x18>;
				scl-gpios = <0x19 0x1d 0x06>;
				sda-gpios = <0x19 0x1c 0x06>;
				phandle = <0x6e>;
			};

			i2c@42540000 {
				compatible = "fsl,imx93-lpi2c\0fsl,imx7ulp-lpi2c";
				reg = <0x42540000 0x10000>;
				#address-cells = <0x01>;
				#size-cells = <0x00>;
				interrupts = <0x00 0x3f 0x04>;
				clocks = <0x05 0x91 0x05 0x0f>;
				clock-names = "per\0ipg";
				dmas = <0x16 0x0a 0x00 0x00 0x16 0x0b 0x00 0x01>;
				dma-names = "tx\0rx";
				status = "disabled";
				clock-frequency = <0x61a80>;
				pinctrl-names = "default\0gpio";
				pinctrl-0 = <0x1a>;
				pinctrl-1 = <0x1b>;
				scl-gpios = <0x19 0x03 0x06>;
				sda-gpios = <0x19 0x02 0x06>;
				phandle = <0x6f>;
			};

			spi@42550000 {
				#address-cells = <0x01>;
				#size-cells = <0x00>;
				compatible = "fsl,imx93-spi\0fsl,imx7ulp-spi";
				reg = <0x42550000 0x10000>;
				interrupts = <0x00 0x41 0x04>;
				clocks = <0x05 0x98 0x05 0x0f>;
				clock-names = "per\0ipg";
				dmas = <0x16 0x0c 0x00 0x00 0x16 0x0d 0x00 0x01>;
				dma-names = "tx\0rx";
				status = "disabled";
				pinctrl-names = "default";
				pinctrl-0 = <0x1c 0x1d>;
				spi-max-frequency = <0x17d7840>;
				phandle = <0x70>;
			};

			spi@42560000 {
				#address-cells = <0x01>;
				#size-cells = <0x00>;
				compatible = "fsl,imx93-spi\0fsl,imx7ulp-spi";
				reg = <0x42560000 0x10000>;
				interrupts = <0x00 0x42 0x04>;
				clocks = <0x05 0x99 0x05 0x0f>;
				clock-names = "per\0ipg";
				dmas = <0x16 0x0e 0x00 0x00 0x16 0x0f 0x00 0x01>;
				dma-names = "tx\0rx";
				status = "okay";
				pinctrl-names = "default";
				pinctrl-0 = <0x1e 0x1f>;
				spi-max-frequency = <0x17d7840>;
				phandle = <0x71>;
			};

			serial@42570000 {
				compatible = "fsl,imx93-lpuart\0fsl,imx8ulp-lpuart";
				reg = <0x42570000 0x1000>;
				interrupts = <0x00 0x44 0x04>;
				clocks = <0x05 0x88>;
				clock-names = "ipg";
				dmas = <0x16 0x11 0x00 0x00 0x16 0x12 0x00 0x01>;
				dma-names = "tx\0rx";
				status = "okay";
				pinctrl-names = "default";
				pinctrl-0 = <0x20>;
				phandle = <0x72>;
			};

			serial@42580000 {
				compatible = "fsl,imx93-lpuart\0fsl,imx8ulp-lpuart";
				reg = <0x42580000 0x1000>;
				interrupts = <0x00 0x45 0x04>;
				clocks = <0x05 0x89>;
				clock-names = "ipg";
				dmas = <0x16 0x13 0x00 0x00 0x16 0x14 0x00 0x01>;
				dma-names = "tx\0rx";
				status = "disabled";
				phandle = <0x73>;
			};

			serial@42590000 {
				compatible = "fsl,imx93-lpuart\0fsl,imx8ulp-lpuart";
				reg = <0x42590000 0x1000>;
				interrupts = <0x00 0x46 0x04>;
				clocks = <0x05 0x8a>;
				clock-names = "ipg";
				dmas = <0x16 0x15 0x00 0x00 0x16 0x16 0x00 0x01>;
				dma-names = "tx\0rx";
				status = "okay";
				pinctrl-names = "default";
				pinctrl-0 = <0x21 0x22>;
				uart-has-rtscts;
				phandle = <0x74>;
			};

			serial@425a0000 {
				compatible = "fsl,imx93-lpuart\0fsl,imx8ulp-lpuart";
				reg = <0x425a0000 0x1000>;
				interrupts = <0x00 0x47 0x04>;
				clocks = <0x05 0x8b>;
				clock-names = "ipg";
				dmas = <0x16 0x17 0x00 0x00 0x16 0x18 0x00 0x01>;
				dma-names = "tx\0rx";
				status = "disabled";
				phandle = <0x75>;
			};

			can@425b0000 {
				compatible = "fsl,imx93-flexcan";
				reg = <0x425b0000 0x10000>;
				interrupts = <0x00 0x33 0x04>;
				clocks = <0x05 0x0f 0x05 0x85>;
				clock-names = "ipg\0per";
				assigned-clocks = <0x05 0x22>;
				assigned-clock-parents = <0x05 0x06>;
				assigned-clock-rates = <0x2625a00>;
				fsl,clk-source = [00];
				fsl,stop-mode = <0x04 0x0c 0x02>;
				status = "disabled";
				phandle = <0x76>;
			};

			spi@425e0000 {
				#address-cells = <0x01>;
				#size-cells = <0x00>;
				compatible = "nxp,imx93-fspi\0nxp,imx8mm-fspi";
				reg = <0x425e0000 0x10000 0x28000000 0x10000000>;
				reg-names = "fspi_base\0fspi_mmap";
				interrupts = <0x00 0x37 0x04>;
				clocks = <0x05 0x73 0x05 0x73>;
				clock-names = "fspi\0fspi_en";
				assigned-clocks = <0x05 0x20>;
				assigned-clock-parents = <0x05 0x05>;
				status = "disabled";
				phandle = <0x77>;
			};

			sai@42650000 {
				compatible = "fsl,imx93-sai";
				reg = <0x42650000 0x10000>;
				interrupts = <0x00 0xaa 0x04>;
				clocks = <0x05 0xbf 0x05 0x00 0x05 0xa4 0x05 0x00 0x05 0x00>;
				clock-names = "bus\0mclk0\0mclk1\0mclk2\0mclk3";
				dmas = <0x16 0x3b 0x00 0x01 0x16 0x3a 0x00 0x00>;
				dma-names = "rx\0tx";
				status = "disabled";
				phandle = <0x78>;
			};

			sai@42660000 {
				compatible = "fsl,imx93-sai";
				reg = <0x42660000 0x10000>;
				interrupts = <0x00 0xab 0x04>;
				clocks = <0x05 0xc0 0x05 0x00 0x05 0xa5 0x05 0x00 0x05 0x00>;
				clock-names = "bus\0mclk0\0mclk1\0mclk2\0mclk3";
				dmas = <0x16 0x3d 0x00 0x01 0x16 0x3c 0x00 0x00>;
				dma-names = "rx\0tx";
				status = "disabled";
				phandle = <0x79>;
			};

			xcvr@42680000 {
				compatible = "fsl,imx93-xcvr";
				reg = <0x42680000 0x800 0x42680800 0x400 0x42680c00 0x80 0x42680e00 0x80>;
				reg-names = "ram\0regs\0rxfifo\0txfifo";
				interrupts = <0x00 0xcb 0x04 0x00 0xcc 0x04>;
				clocks = <0x05 0x0f 0x05 0xb4 0x05 0x00 0x05 0xb3>;
				clock-names = "ipg\0phy\0spba\0pll_ipg";
				dmas = <0x16 0x41 0x00 0x01 0x16 0x42 0x00 0x00>;
				dma-names = "rx\0tx";
				status = "disabled";
				phandle = <0x7a>;
			};

			serial@42690000 {
				compatible = "fsl,imx93-lpuart\0fsl,imx8ulp-lpuart";
				reg = <0x42690000 0x1000>;
				interrupts = <0x00 0xd2 0x04>;
				clocks = <0x05 0x8c>;
				clock-names = "ipg";
				dmas = <0x16 0x57 0x00 0x00 0x16 0x58 0x00 0x01>;
				dma-names = "tx\0rx";
				status = "disabled";
				phandle = <0x7b>;
			};

			serial@426a0000 {
				compatible = "fsl,imx93-lpuart\0fsl,imx8ulp-lpuart";
				reg = <0x426a0000 0x1000>;
				interrupts = <0x00 0xd3 0x04>;
				clocks = <0x05 0x8d>;
				clock-names = "ipg";
				dmas = <0x16 0x59 0x00 0x00 0x16 0x5a 0x00 0x01>;
				dma-names = "tx\0rx";
				status = "disabled";
				phandle = <0x7c>;
			};

			i2c@426b0000 {
				compatible = "fsl,imx93-lpi2c\0fsl,imx7ulp-lpi2c";
				reg = <0x426b0000 0x10000>;
				#address-cells = <0x01>;
				#size-cells = <0x00>;
				interrupts = <0x00 0xc3 0x04>;
				clocks = <0x05 0x92 0x05 0x0f>;
				clock-names = "per\0ipg";
				dmas = <0x16 0x47 0x00 0x00 0x16 0x48 0x00 0x01>;
				dma-names = "tx\0rx";
				status = "disabled";
				clock-frequency = <0x61a80>;
				pinctrl-names = "default\0gpio";
				pinctrl-0 = <0x23>;
				pinctrl-1 = <0x24>;
				scl-gpios = <0x19 0x17 0x06>;
				sda-gpios = <0x19 0x16 0x06>;
				phandle = <0x7d>;
			};

			i2c@426c0000 {
				compatible = "fsl,imx93-lpi2c\0fsl,imx7ulp-lpi2c";
				reg = <0x426c0000 0x10000>;
				#address-cells = <0x01>;
				#size-cells = <0x00>;
				interrupts = <0x00 0xc4 0x04>;
				clocks = <0x05 0x93 0x05 0x0f>;
				clock-names = "per\0ipg";
				dmas = <0x16 0x49 0x00 0x00 0x16 0x4a 0x00 0x01>;
				dma-names = "tx\0rx";
				status = "disabled";
				phandle = <0x7e>;
			};

			i2c@426d0000 {
				compatible = "fsl,imx93-lpi2c\0fsl,imx7ulp-lpi2c";
				reg = <0x426d0000 0x10000>;
				#address-cells = <0x01>;
				#size-cells = <0x00>;
				interrupts = <0x00 0xc5 0x04>;
				clocks = <0x05 0x94 0x05 0x0f>;
				clock-names = "per\0ipg";
				dmas = <0x16 0x4b 0x00 0x00 0x16 0x4c 0x00 0x01>;
				dma-names = "tx\0rx";
				status = "disabled";
				clock-frequency = <0x61a80>;
				pinctrl-names = "default\0gpio";
				pinctrl-0 = <0x25>;
				pinctrl-1 = <0x26>;
				scl-gpios = <0x19 0x09 0x06>;
				sda-gpios = <0x19 0x08 0x06>;
				phandle = <0x7f>;
			};

			i2c@426e0000 {
				compatible = "fsl,imx93-lpi2c\0fsl,imx7ulp-lpi2c";
				reg = <0x426e0000 0x10000>;
				#address-cells = <0x01>;
				#size-cells = <0x00>;
				interrupts = <0x00 0xc6 0x04>;
				clocks = <0x05 0x95 0x05 0x0f>;
				clock-names = "per\0ipg";
				dmas = <0x16 0x4d 0x00 0x00 0x16 0x4e 0x00 0x01>;
				dma-names = "tx\0rx";
				status = "disabled";
				clock-frequency = <0x61a80>;
				pinctrl-names = "default\0gpio";
				pinctrl-0 = <0x27>;
				pinctrl-1 = <0x28>;
				scl-gpios = <0x19 0x0b 0x06>;
				sda-gpios = <0x19 0x0a 0x06>;
				phandle = <0x80>;
			};

			spi@426f0000 {
				#address-cells = <0x01>;
				#size-cells = <0x00>;
				compatible = "fsl,imx93-spi\0fsl,imx7ulp-spi";
				reg = <0x426f0000 0x10000>;
				interrupts = <0x00 0xbf 0x04>;
				clocks = <0x05 0x9a 0x05 0x0f>;
				clock-names = "per\0ipg";
				dmas = <0x16 0x4f 0x00 0x00 0x16 0x50 0x00 0x01>;
				dma-names = "tx\0rx";
				status = "disabled";
				phandle = <0x81>;
			};

			spi@42700000 {
				#address-cells = <0x01>;
				#size-cells = <0x00>;
				compatible = "fsl,imx93-spi\0fsl,imx7ulp-spi";
				reg = <0x42700000 0x10000>;
				interrupts = <0x00 0xc0 0x04>;
				clocks = <0x05 0x9b 0x05 0x0f>;
				clock-names = "per\0ipg";
				dmas = <0x16 0x51 0x00 0x00 0x16 0x52 0x00 0x01>;
				dma-names = "tx\0rx";
				status = "disabled";
				phandle = <0x82>;
			};

			spi@42710000 {
				#address-cells = <0x01>;
				#size-cells = <0x00>;
				compatible = "fsl,imx93-spi\0fsl,imx7ulp-spi";
				reg = <0x42710000 0x10000>;
				interrupts = <0x00 0xc1 0x04>;
				clocks = <0x05 0x9c 0x05 0x0f>;
				clock-names = "per\0ipg";
				dmas = <0x16 0x53 0x00 0x00 0x16 0x54 0x00 0x01>;
				dma-names = "tx\0rx";
				status = "disabled";
				phandle = <0x83>;
			};

			spi@42720000 {
				#address-cells = <0x01>;
				#size-cells = <0x00>;
				compatible = "fsl,imx93-spi\0fsl,imx7ulp-spi";
				reg = <0x42720000 0x10000>;
				interrupts = <0x00 0xc2 0x04>;
				clocks = <0x05 0x9d 0x05 0x0f>;
				clock-names = "per\0ipg";
				dmas = <0x16 0x55 0x00 0x00 0x16 0x56 0x00 0x01>;
				dma-names = "tx\0rx";
				status = "disabled";
				phandle = <0x84>;
			};

			flexio@425c0000 {
				#address-cells = <0x01>;
				#size-cells = <0x01>;
				compatible = "nxp,imx-flexio";
				reg = <0x425c0000 0x10000>;
				interrupts = <0x00 0x35 0x04>;
				clocks = <0x05 0x78 0x05 0x78>;
				clock-names = "per\0ipg";
				assigned-clocks = <0x05 0x78>;
				assigned-clock-parents = <0x05 0x14>;
				assigned-clock-rates = <0x16e3600>;
				status = "disabled";
				phandle = <0x85>;

				i2c-master {
					#address-cells = <0x01>;
					#size-cells = <0x00>;
					compatible = "nxp,imx-flexio-i2c-master";
					clock-frequency = <0x186a0>;
					status = "disabled";
					phandle = <0x86>;
				};
			};
		};

		bus@42800000 {
			compatible = "fsl,aips-bus\0simple-bus";
			reg = <0x42800000 0x800000>;
			#address-cells = <0x01>;
			#size-cells = <0x01>;
			ranges;
			phandle = <0x87>;

			mmc@42850000 {
				compatible = "fsl,imx93-usdhc\0fsl,imx8mm-usdhc";
				reg = <0x42850000 0x10000>;
				interrupts = <0x00 0x56 0x04>;
				clocks = <0x05 0x0f 0x05 0x11 0x05 0xa0>;
				clock-names = "ipg\0ahb\0per";
				assigned-clocks = <0x05 0x3d>;
				assigned-clock-parents = <0x05 0x05>;
				assigned-clock-rates = <0x17d78400>;
				bus-width = <0x08>;
				fsl,tuning-start-tap = <0x28>;
				fsl,tuning-step = <0x01>;
				status = "okay";
				pinctrl-names = "default";
				pinctrl-0 = <0x29>;
				vmmc-supply = <0x2a>;
				vqmmc-supply = <0x2a>;
				no-1-8-v;
				non-removable;
				phandle = <0x88>;
			};

			mmc@42860000 {
				compatible = "fsl,imx93-usdhc\0fsl,imx8mm-usdhc";
				reg = <0x42860000 0x10000>;
				interrupts = <0x00 0x57 0x04>;
				clocks = <0x05 0x0f 0x05 0x11 0x05 0xa1>;
				clock-names = "ipg\0ahb\0per";
				assigned-clocks = <0x05 0x3e>;
				assigned-clock-parents = <0x05 0x05>;
				assigned-clock-rates = <0x17d78400>;
				bus-width = <0x04>;
				fsl,tuning-start-tap = <0x14>;
				fsl,tuning-step = <0x02>;
				status = "disabled";
				phandle = <0x89>;
			};

			ethernet@42890000 {
				compatible = "fsl,imx93-fec\0fsl,imx8mp-fec\0fsl,imx8mq-fec";
				reg = <0x42890000 0x10000>;
				interrupts = <0x00 0xb3 0x04 0x00 0xb4 0x04 0x00 0xb5 0x04 0x00 0xb6 0x04>;
				clocks = <0x05 0xb6 0x05 0xb6 0x05 0x5d 0x05 0x5f 0x05 0x60>;
				clock-names = "ipg\0ahb\0ptp\0enet_clk_ref\0enet_out";
				assigned-clocks = <0x05 0x5d 0x05 0x5f 0x05 0x60>;
				assigned-clock-parents = <0x05 0x06 0x05 0x04 0x05 0x06>;
				assigned-clock-rates = <0x5f5e100 0xee6b280 0x2faf080>;
				fsl,num-tx-queues = <0x03>;
				fsl,num-rx-queues = <0x03>;
				fsl,stop-mode = <0x04 0x0c 0x01>;
				status = "disabled";
				phy-supply = <0x2a>;
				phandle = <0x8a>;

				mdio {
					#address-cells = <0x01>;
					#size-cells = <0x00>;
				};
			};

			ethernet@428a0000 {
				compatible = "nxp,imx93-dwmac-eqos\0snps,dwmac-5.10a";
				reg = <0x428a0000 0x10000>;
				interrupts = <0x00 0xb7 0x04 0x00 0xb8 0x04>;
				interrupt-names = "eth_wake_irq\0macirq";
				clocks = <0x05 0xb7 0x05 0xb7 0x05 0x5e 0x05 0x5c 0x05 0xb7>;
				clock-names = "stmmaceth\0pclk\0ptp_ref\0tx\0mem";
				assigned-clocks = <0x05 0x5e 0x05 0x5c>;
				assigned-clock-parents = <0x05 0x06 0x05 0x04>;
				assigned-clock-rates = <0x5f5e100 0xee6b280>;
				intf_mode = <0x04 0x28>;
				clk_csr = <0x00>;
				nvmem-cells = <0x2b>;
				nvmem-cell-names = "mac-address";
				status = "disabled";
				phy-supply = <0x2a>;
				phandle = <0x8b>;

				mdio {
					compatible = "snps,dwmac-mdio";
					#address-cells = <0x01>;
					#size-cells = <0x00>;
				};
			};

			mmc@428b0000 {
				compatible = "fsl,imx93-usdhc\0fsl,imx8mm-usdhc";
				reg = <0x428b0000 0x10000>;
				interrupts = <0x00 0xcd 0x04>;
				clocks = <0x05 0x0f 0x05 0x11 0x05 0xa2>;
				clock-names = "ipg\0ahb\0per";
				assigned-clocks = <0x05 0x3f>;
				assigned-clock-parents = <0x05 0x05>;
				assigned-clock-rates = <0x17d78400>;
				bus-width = <0x04>;
				fsl,tuning-start-tap = <0x14>;
				fsl,tuning-step = <0x02>;
				status = "disabled";
				pinctrl-names = "default";
				pinctrl-0 = <0x2c>;
				vmmc-supply = <0x2a>;
				vqmmc-supply = <0x2a>;
				no-1-8-v;
				no-sdio;
				no-mmc;
				phandle = <0x8c>;
			};

			epxp@4ae20000 {
				compatible = "fsl,imx93-pxp-dma";
				reg = <0x4ae20000 0x10000>;
				interrupts = <0x00 0xad 0x04 0x00 0xae 0x04>;
				clocks = <0x05 0x4e 0x05 0x4d>;
				clock-names = "pxp_ipg\0pxp_axi";
				pxp-gpr = <0x2d>;
				power-domains = <0x2d 0x02>;
				status = "disabled";
				phandle = <0x8d>;
			};

			camera {
				compatible = "fsl,mxc-md\0simple-bus";
				#address-cells = <0x01>;
				#size-cells = <0x01>;
				ranges;
				status = "disabled";
				phandle = <0x8e>;

				isi@4ae40000 {
					compatible = "fsl,imx93-isi\0fsl,imx8-isi";
					reg = <0x4ae40000 0x10000>;
					interrupts = <0x00 0xac 0x04>;
					clocks = <0x05 0xab 0x05 0x4d>;
					clock-names = "per\0axi";
					assigned-clocks = <0x05 0x4d 0x05 0x4e>;
					assigned-clock-parents = <0x05 0x05 0x05 0x06>;
					assigned-clock-rates = <0x17d78400 0x7f28155>;
					interface = <0x02 0x00 0x02>;
					no-reset-control;
					power-domains = <0x2d 0x04>;
					gasket = <0x2d>;
					status = "disabled";
					phandle = <0x8f>;

					cap_device {
						compatible = "imx-isi-capture";
						status = "disabled";
					};
				};

				csi@4ae00000 {
					compatible = "fsl,dwc-mipi-csi2-host";
					reg = <0x4ae00000 0x10000>;
					interrupts = <0x00 0xaf 0x04>;
					clocks = <0x05 0xa6 0x05 0x51 0x05 0x53>;
					clock-names = "clk_core\0clk_pixel\0phy_cfg";
					assigned-clocks = <0x05 0x51 0x05 0x53>;
					assigned-clock-parents = <0x05 0x0a 0x05 0x01>;
					assigned-clock-rates = <0x8583b00 0x16e3600>;
					gasket = <0x2d>;
					power-domains = <0x2d 0x01>;
					status = "disabled";
					phandle = <0x90>;
				};

				pcsi@4ac10070 {
					compatible = "fsl,imx93-parallel-csi";
					reg = <0x4ac10070 0x10>;
					clocks = <0x05 0xa6 0x05 0x4e>;
					clock-names = "pixel\0ipg";
					assigned-clocks = <0x05 0x51>;
					assigned-clock-parents = <0x05 0x0a>;
					assigned-clock-rates = "\bX;";
					pi_gpr = <0x2d>;
					power-domains = <0x2d 0x01>;
					status = "disabled";
					phandle = <0x91>;
				};
			};
		};

		gpio@43810080 {
			#address-cells = <0x01>;
			#size-cells = <0x00>;
			compatible = "fsl,imx93-gpio\0fsl,imx7ulp-gpio";
			reg = <0x43810080 0x1000 0x43810040 0x40>;
			gpio-controller;
			#gpio-cells = <0x02>;
			interrupts = <0x00 0x39 0x04>;
			interrupt-controller;
			#interrupt-cells = <0x02>;
			clocks = <0x05 0x75 0x05 0x75>;
			clock-names = "gpio\0port";
			gpio-ranges = <0x2e 0x00 0x04 0x1e>;
			phandle = <0x19>;
		};

		gpio@43820080 {
			compatible = "fsl,imx93-gpio\0fsl,imx7ulp-gpio";
			reg = <0x43820080 0x1000 0x43820040 0x40>;
			gpio-controller;
			#gpio-cells = <0x02>;
			interrupts = <0x00 0x3b 0x04>;
			interrupt-controller;
			#interrupt-cells = <0x02>;
			clocks = <0x05 0x76 0x05 0x76>;
			clock-names = "gpio\0port";
			gpio-ranges = <0x2e 0x00 0x54 0x08 0x2e 0x08 0x42 0x12 0x2e 0x1a 0x22 0x02 0x2e 0x1c 0x00 0x04>;
			phandle = <0x92>;
		};

		gpio@43830080 {
			compatible = "fsl,imx93-gpio\0fsl,imx7ulp-gpio";
			reg = <0x43830080 0x1000 0x43830040 0x40>;
			gpio-controller;
			#gpio-cells = <0x02>;
			interrupts = <0x00 0xbd 0x04>;
			interrupt-controller;
			#interrupt-cells = <0x02>;
			clocks = <0x05 0x77 0x05 0x77>;
			clock-names = "gpio\0port";
			gpio-ranges = <0x2e 0x00 0x26 0x1c 0x2e 0x1c 0x24 0x02>;
			phandle = <0x93>;
		};

		gpio@47400080 {
			compatible = "fsl,imx93-gpio\0fsl,imx7ulp-gpio";
			reg = <0x47400080 0x1000 0x47400040 0x40>;
			gpio-controller;
			#gpio-cells = <0x02>;
			interrupts = <0x00 0x0a 0x04>;
			interrupt-controller;
			#interrupt-cells = <0x02>;
			clocks = <0x05 0x74 0x05 0x74>;
			clock-names = "gpio\0port";
			gpio-ranges = <0x2e 0x00 0x5c 0x10>;
			phandle = <0x0e>;
		};

		efuse@47510000 {
			compatible = "fsl,imx93-ocotp\0syscon\0simple-mfd";
			reg = <0x47510000 0x10000>;
			#address-cells = <0x01>;
			#size-cells = <0x01>;
			phandle = <0x94>;

			soc-uid@c0 {
				reg = <0xc0 0x10>;
				phandle = <0x2f>;
			};

			mac-address@4ec {
				reg = <0x4ec 0x06>;
				phandle = <0x95>;
			};

			mac-address@4f2 {
				reg = <0x4f2 0x06>;
				phandle = <0x2b>;
			};

			imx93-soc {
				compatible = "fsl,imx93-soc";
				nvmem-cells = <0x2f>;
				nvmem-cell-names = "soc_unique_id";
				phandle = <0x96>;
			};
		};

		mailbox@47520000 {
			compatible = "fsl,imx93-mu-s4";
			reg = <0x47520000 0x10000>;
			interrupts = <0x00 0x1f 0x04 0x00 0x1e 0x04>;
			interrupt-names = "tx\0rx";
			#mbox-cells = <0x02>;
			phandle = <0x34>;
		};

		system-controller@4ac10000 {
			compatible = "fsl,imx93-media-blk-ctrl\0syscon\0simple-mfd";
			reg = <0x4ac10000 0x70>;
			power-domains = <0x30>;
			clocks = <0x05 0x4e 0x05 0x4d 0x05 0xac 0x05 0x50 0x05 0x51 0x05 0xaa 0x05 0xa9 0x05 0xab 0x05 0xa6 0x05 0xa7>;
			clock-names = "apb\0axi\0nic\0disp\0cam\0pxp\0lcdif\0isi\0csi\0dsi";
			#power-domain-cells = <0x01>;
			phandle = <0x2d>;

			dphy {
				compatible = "fsl,imx93-mipi-dphy";
				clocks = <0x05 0x53 0x05 0x01>;
				clock-names = "phy_cfg\0phy_ref";
				assigned-clocks = <0x05 0x53>;
				assigned-clock-parents = <0x05 0x01>;
				assigned-clock-rates = <0x16e3600>;
				#phy-cells = <0x00>;
				power-domains = <0x2d 0x00>;
				status = "disabled";
				phandle = <0x36>;
			};

			dpi {
				compatible = "fsl,imx93-parallel-display-format";
				power-domains = <0x30>;
				status = "disabled";
				phandle = <0x97>;

				ports {
					#address-cells = <0x01>;
					#size-cells = <0x00>;

					port@0 {
						reg = <0x00>;

						endpoint {
							remote-endpoint = <0x31>;
							phandle = <0x3a>;
						};
					};
				};
			};
		};

		ldb@4ac10020 {
			#address-cells = <0x01>;
			#size-cells = <0x00>;
			compatible = "fsl,imx93-ldb";
			reg = <0x4ac10020 0x04>;
			clocks = <0x05 0xa8>;
			clock-names = "ldb";
			assigned-clocks = <0x05 0x4f>;
			assigned-clock-parents = <0x05 0x0a>;
			gpr = <0x2d>;
			power-domains = <0x30>;
			status = "disabled";
			phandle = <0x98>;

			lvds-channel@0 {
				#address-cells = <0x01>;
				#size-cells = <0x00>;
				reg = <0x00>;
				phys = <0x32>;
				phy-names = "ldb_phy";
				status = "disabled";

				port@0 {
					reg = <0x00>;

					endpoint {
						remote-endpoint = <0x33>;
						phandle = <0x39>;
					};
				};
			};
		};

		phy@4ac10024 {
			compatible = "fsl,imx93-lvds-phy";
			reg = <0x4ac10024 0x04>;
			#address-cells = <0x01>;
			#size-cells = <0x00>;
			gpr = <0x2d>;
			clocks = <0x05 0x4e>;
			clock-names = "apb";
			power-domains = <0x30>;
			status = "disabled";
			phandle = <0x99>;

			port@0 {
				reg = <0x00>;
				#phy-cells = <0x00>;
				phandle = <0x32>;
			};
		};

		ele-mu {
			compatible = "fsl,imx93-ele";
			mboxes = <0x34 0x00 0x00 0x34 0x01 0x00>;
			mbox-names = "tx\0rx";
			fsl,ele_mu_did = <0x03>;
			fsl,ele_mu_id = <0x02>;
			fsl,ele_mu_max_users = <0x04>;
			status = "okay";
			memory-region = <0x35>;
			phandle = <0x9a>;
		};

		dsi@4ae10000 {
			compatible = "fsl,imx93-mipi-dsi";
			reg = <0x4ae10000 0x4000>;
			interrupts = <0x00 0xb1 0x04>;
			clocks = <0x05 0x52 0x05 0xa7 0x05 0x50>;
			clock-names = "byte\0pclk\0pixel";
			assigned-clocks = <0x05 0x52 0x05 0x4e>;
			assigned-clock-parents = <0x05 0x03 0x05 0x06>;
			assigned-clock-rates = <0x1312d00 0x7f28155>;
			phys = <0x36>;
			phy-names = "dphy";
			power-domains = <0x2d 0x00>;
			status = "disabled";
			phandle = <0x9b>;

			ports {
				#address-cells = <0x01>;
				#size-cells = <0x00>;

				port@0 {
					reg = <0x00>;

					endpoint {
						remote-endpoint = <0x37>;
						phandle = <0x38>;
					};
				};
			};
		};

		lcd-controller@4ae30000 {
			compatible = "fsl,imx93-lcdif";
			reg = <0x4ae30000 0x10000>;
			interrupts = <0x00 0xb0 0x04>;
			fsl,gpr = <0x2d>;
			clocks = <0x05 0x50 0x05 0x4d 0x05 0xa9>;
			clock-names = "pix\0disp-axi\0disp-apb";
			assigned-clocks = <0x05 0x0a 0x05 0x50 0x05 0x4d 0x05 0x4e>;
			assigned-clock-parents = <0x05 0x01 0x05 0x0a 0x05 0x05 0x05 0x06>;
			power-domains = <0x2d 0x03>;
			status = "disabled";
			phandle = <0x9c>;

			port {
				#address-cells = <0x01>;
				#size-cells = <0x00>;
				phandle = <0x3f>;

				endpoint@0 {
					reg = <0x00>;
					remote-endpoint = <0x38>;
					phandle = <0x37>;
				};

				endpoint@1 {
					reg = <0x01>;
					remote-endpoint = <0x39>;
					phandle = <0x33>;
				};

				endpoint@2 {
					reg = <0x02>;
					remote-endpoint = <0x3a>;
					phandle = <0x31>;
				};
			};
		};

		usb@4c100000 {
			compatible = "fsl,imx8mm-usb\0fsl,imx7d-usb";
			reg = <0x4c100000 0x200>;
			interrupts = <0x00 0xbb 0x04>;
			clocks = <0x05 0xad 0x05 0xb5>;
			clock-names = "usb_ctrl_root_clk\0usb_wakeup_clk";
			assigned-clocks = <0x05 0x47>;
			assigned-clock-parents = <0x05 0x06>;
			assigned-clock-rates = <0x7ed6b40>;
			fsl,usbphy = <0x3b>;
			fsl,usbmisc = <0x3c 0x00>;
			status = "okay";
			dr_mode = "peripheral";
			hnp-disable;
			srp-disable;
			adp-disable;
			disable-over-current;
			samsung,picophy-pre-emp-curr-control = <0x03>;
			samsung,picophy-dc-vol-level-adjust = <0x07>;
			phandle = <0x9d>;
		};

		usbmisc@4c100200 {
			compatible = "fsl,imx8mm-usbmisc\0fsl,imx7d-usbmisc";
			#index-cells = <0x01>;
			reg = <0x4c100200 0x200>;
			phandle = <0x3c>;
		};

		usb@4c200000 {
			compatible = "fsl,imx8mm-usb\0fsl,imx7d-usb";
			reg = <0x4c200000 0x200>;
			interrupts = <0x00 0xbc 0x04>;
			clocks = <0x05 0xad 0x05 0xb5>;
			clock-names = "usb_ctrl_root_clk\0usb_wakeup_clk";
			assigned-clocks = <0x05 0x47>;
			assigned-clock-parents = <0x05 0x06>;
			assigned-clock-rates = <0x7ed6b40>;
			fsl,usbphy = <0x3d>;
			fsl,usbmisc = <0x3e 0x00>;
			status = "okay";
			dr_mode = "host";
			hnp-disable;
			srp-disable;
			adp-disable;
			disable-over-current;
			samsung,picophy-pre-emp-curr-control = <0x03>;
			samsung,picophy-dc-vol-level-adjust = <0x07>;
			phandle = <0x9e>;
		};

		usbmisc@4c200200 {
			compatible = "fsl,imx8mm-usbmisc\0fsl,imx7d-usbmisc";
			#index-cells = <0x01>;
			reg = <0x4c200200 0x200>;
			phandle = <0x3e>;
		};

		blk-ctrl@4e010000 {
			compatible = "nxp,blk-ctrl-ddrmix\0syscon\0simple-mfd";
			reg = <0x4e010000 0x1000>;
			phandle = <0x40>;
		};

		memory-controller@4e300000 {
			compatible = "nxp,imx9-memory-controller\0simple-mfd";
			reg = <0x4e300000 0x2000>;
			interrupts = <0x00 0x5b 0x04>;
			little-endian;
			#address-cells = <0x01>;
			#size-cells = <0x01>;
			ranges;
			phandle = <0x9f>;

			ddr-pmu@4e300dc0 {
				compatible = "fsl,imx93-ddr-pmu";
				reg = <0x4e300dc0 0x200>;
				interrupts = <0x00 0x5a 0x04>;
			};
		};
	};

	display-subsystem {
		compatible = "fsl,imx-display-subsystem";
		ports = <0x3f>;
	};

	imx93-lpm {
		compatible = "nxp,imx93-lpm";
		regmap = <0x40>;
		clocks = <0x05 0x0e 0x05 0x11 0x05 0xc5 0x05 0x4d 0x05 0x0b 0x05 0xc8 0x05 0x4c 0x05 0x03 0x05 0x04 0x05 0x05 0x05 0x06 0x05 0x07 0x05 0x08>;
		clock-names = "m33_root\0wakeup_axi\0nic_axi\0media_axi\0a55_periph\0a55_core\0ml_axi\0sys_pll_pfd0\0sys_pll_pfd0_div2\0sys_pll_pfd1\0sys_pll_pfd1_div2\0sys_pll_pfd2\0sys_pll_pfd2_div2";
		status = "disabled";
		phandle = <0xa0>;
	};

	chosen {
		stdout-path = "serial0:115200n8";

		overlays {
		};
	};

	lvds-panel {
		compatible = "panel-lvds";
		label = "PANEL SPECIFIC OVERLAY MISSING";
		phandle = <0xa1>;
	};

	reserved-memory {
		#address-cells = <0x02>;
		#size-cells = <0x02>;
		ranges;

		linux,cma {
			compatible = "shared-dma-pool";
			reusable;
			size = <0x00 0x10000000>;
			linux,cma-default;
		};

		ele-reserved@a4120000 {
			compatible = "shared-dma-pool";
			reg = <0x00 0xa4120000 0x00 0x100000>;
			no-map;
			phandle = <0x35>;
		};
	};

	regulator-adc-vref {
		compatible = "regulator-fixed";
		regulator-name = "vref_1v8";
		regulator-min-microvolt = <0x1b7740>;
		regulator-max-microvolt = <0x1b7740>;
		vin-supply = <0x41>;
		phandle = <0xa2>;
	};

	regulator-3v3 {
		compatible = "regulator-fixed";
		regulator-name = "vdd_3v3";
		regulator-min-microvolt = <0x325aa0>;
		regulator-max-microvolt = <0x325aa0>;
		vin-supply = <0x2a>;
		phandle = <0xa3>;
	};

	__symbols__ {
		cpu_pd_wait = "/cpus/idle-states/cpu-pd-wait";
		A55_0 = "/cpus/cpu@0";
		A55_1 = "/cpus/cpu@100";
		osc_32k = "/clock-osc-32k";
		osc_24m = "/clock-osc-24m";
		clk_ext1 = "/clock-ext1";
		mqs1 = "/mqs1";
		mqs2 = "/mqs2";
		gic = "/interrupt-controller@48000000";
		usbphynop1 = "/usbphynop1";
		usbphynop2 = "/usbphynop2";
		cpu_alert = "/thermal-zones/cpu-thermal/trips/cpu-alert";
		cpu_crit = "/thermal-zones/cpu-thermal/trips/cpu-crit";
		aips1 = "/soc@0/bus@44000000";
		anomix_ns_gpr = "/soc@0/bus@44000000/syscon@44210000";
		mu1 = "/soc@0/bus@44000000/mailbox@44230000";
		edma1 = "/soc@0/bus@44000000/dma-controller@44000000";
		system_counter = "/soc@0/bus@44000000/timer@44290000";
		tpm1 = "/soc@0/bus@44000000/pwm@44310000";
		tpm2 = "/soc@0/bus@44000000/pwm@44320000";
		i3c1 = "/soc@0/bus@44000000/i3c-master@44330000";
		lpi2c1 = "/soc@0/bus@44000000/i2c@44340000";
		pmic = "/soc@0/bus@44000000/i2c@44340000/pmic@25";
		buck1 = "/soc@0/bus@44000000/i2c@44340000/pmic@25/regulators/BUCK1";
		buck2 = "/soc@0/bus@44000000/i2c@44340000/pmic@25/regulators/BUCK2";
		buck4 = "/soc@0/bus@44000000/i2c@44340000/pmic@25/regulators/BUCK4";
		buck5 = "/soc@0/bus@44000000/i2c@44340000/pmic@25/regulators/BUCK5";
		buck6 = "/soc@0/bus@44000000/i2c@44340000/pmic@25/regulators/BUCK6";
		ldo1 = "/soc@0/bus@44000000/i2c@44340000/pmic@25/regulators/LDO1";
		ldo2 = "/soc@0/bus@44000000/i2c@44340000/pmic@25/regulators/LDO2";
		ldo3 = "/soc@0/bus@44000000/i2c@44340000/pmic@25/regulators/LDO3";
		ldo4 = "/soc@0/bus@44000000/i2c@44340000/pmic@25/regulators/LDO4";
		ldo5 = "/soc@0/bus@44000000/i2c@44340000/pmic@25/regulators/LDO5";
		lpi2c2 = "/soc@0/bus@44000000/i2c@44350000";
		lpspi1 = "/soc@0/bus@44000000/spi@44360000";
		lpspi2 = "/soc@0/bus@44000000/spi@44370000";
		lpuart1 = "/soc@0/bus@44000000/serial@44380000";
		lpuart2 = "/soc@0/bus@44000000/serial@44390000";
		flexcan1 = "/soc@0/bus@44000000/can@443a0000";
		sai1 = "/soc@0/bus@44000000/sai@443b0000";
		iomuxc = "/soc@0/bus@44000000/pinctrl@443c0000";
		pinctrl_flexcan2 = "/soc@0/bus@44000000/pinctrl@443c0000/flexcan2grp";
		pinctrl_flexspi = "/soc@0/bus@44000000/pinctrl@443c0000/flexspigrp";
		pinctrl_lpi2c1 = "/soc@0/bus@44000000/pinctrl@443c0000/lpi2c1grp";
		pinctrl_lpi2c1_gpio = "/soc@0/bus@44000000/pinctrl@443c0000/lpi2c1-gpiogrp";
		pinctrl_lpi2c2 = "/soc@0/bus@44000000/pinctrl@443c0000/lpi2c2grp";
		pinctrl_lpi2c2_gpio = "/soc@0/bus@44000000/pinctrl@443c0000/lpi2c2-gpiogrp";
		pinctrl_lpi2c3 = "/soc@0/bus@44000000/pinctrl@443c0000/lpi2c3grp";
		pinctrl_lpi2c3_gpio = "/soc@0/bus@44000000/pinctrl@443c0000/lpi2c3-gpiogrp";
		pinctrl_lpi2c4 = "/soc@0/bus@44000000/pinctrl@443c0000/lpi2c4grp";
		pinctrl_lpi2c4_gpio = "/soc@0/bus@44000000/pinctrl@443c0000/lpi2c4-gpiogrp";
		pinctrl_lpi2c5 = "/soc@0/bus@44000000/pinctrl@443c0000/lpi2c5grp";
		pinctrl_lpi2c5_gpio = "/soc@0/bus@44000000/pinctrl@443c0000/lpi2c5-gpiogrp";
		pinctrl_lpi2c7 = "/soc@0/bus@44000000/pinctrl@443c0000/lpi2c7grp";
		pinctrl_lpi2c7_gpio = "/soc@0/bus@44000000/pinctrl@443c0000/lpi2c7-gpiogrp";
		pinctrl_lpi2c8 = "/soc@0/bus@44000000/pinctrl@443c0000/lpi2c8grp";
		pinctrl_lpi2c8_gpio = "/soc@0/bus@44000000/pinctrl@443c0000/lpi2c8-gpiogrp";
		pinctrl_lpspi3 = "/soc@0/bus@44000000/pinctrl@443c0000/lpspi3-grp";
		pinctrl_lpspi3_cs = "/soc@0/bus@44000000/pinctrl@443c0000/lpspi3-csgrp";
		pinctrl_lpspi4 = "/soc@0/bus@44000000/pinctrl@443c0000/lpspi4-grp";
		pinctrl_lpspi4_cs = "/soc@0/bus@44000000/pinctrl@443c0000/lpspi4-csgrp";
		pinctrl_pmic_int = "/soc@0/bus@44000000/pinctrl@443c0000/pmic-intgrp";
		pinctrl_uart1 = "/soc@0/bus@44000000/pinctrl@443c0000/uart1grp";
		pinctrl_uart3 = "/soc@0/bus@44000000/pinctrl@443c0000/uart3grp";
		pinctrl_uart5 = "/soc@0/bus@44000000/pinctrl@443c0000/uart5grp";
		pinctrl_uart5_rtscts = "/soc@0/bus@44000000/pinctrl@443c0000/uart5-rtsctsgrp";
		pinctrl_usdhc1 = "/soc@0/bus@44000000/pinctrl@443c0000/usdhc1grp";
		pinctrl_usdhc3 = "/soc@0/bus@44000000/pinctrl@443c0000/usdhc3grp";
		pinctrl_usdhc3_cd = "/soc@0/bus@44000000/pinctrl@443c0000/usdhc3-cdgrp";
		bbnsm = "/soc@0/bus@44000000/bbnsm@44440000";
		bbnsm_rtc = "/soc@0/bus@44000000/bbnsm@44440000/rtc";
		bbnsm_pwrkey = "/soc@0/bus@44000000/bbnsm@44440000/pwrkey";
		clk = "/soc@0/bus@44000000/clock-controller@44450000";
		src = "/soc@0/bus@44000000/system-controller@44460000";
		mediamix = "/soc@0/bus@44000000/system-controller@44460000/power-domain@44462400";
		mlmix = "/soc@0/bus@44000000/system-controller@44460000/power-domain@44461800";
		anatop = "/soc@0/bus@44000000/anatop@44480000";
		tmu = "/soc@0/bus@44000000/tmu@44482000";
		micfil = "/soc@0/bus@44000000/micfil@44520000";
		adc1 = "/soc@0/bus@44000000/adc@44530000";
		aips2 = "/soc@0/bus@42000000";
		edma2 = "/soc@0/bus@42000000/dma-controller@42000000";
		wakeupmix_gpr = "/soc@0/bus@42000000/syscon@42420000";
		mu2 = "/soc@0/bus@42000000/mailbox@42440000";
		wdog3 = "/soc@0/bus@42000000/wdog@42490000";
		tpm3 = "/soc@0/bus@42000000/pwm@424e0000";
		tpm4 = "/soc@0/bus@42000000/pwm@424f0000";
		tpm5 = "/soc@0/bus@42000000/pwm@42500000";
		tpm6 = "/soc@0/bus@42000000/pwm@42510000";
		i3c2 = "/soc@0/bus@42000000/i3c-master@42520000";
		lpi2c3 = "/soc@0/bus@42000000/i2c@42530000";
		lpi2c4 = "/soc@0/bus@42000000/i2c@42540000";
		lpspi3 = "/soc@0/bus@42000000/spi@42550000";
		lpspi4 = "/soc@0/bus@42000000/spi@42560000";
		lpuart3 = "/soc@0/bus@42000000/serial@42570000";
		lpuart4 = "/soc@0/bus@42000000/serial@42580000";
		lpuart5 = "/soc@0/bus@42000000/serial@42590000";
		lpuart6 = "/soc@0/bus@42000000/serial@425a0000";
		flexcan2 = "/soc@0/bus@42000000/can@425b0000";
		flexspi1 = "/soc@0/bus@42000000/spi@425e0000";
		sai2 = "/soc@0/bus@42000000/sai@42650000";
		sai3 = "/soc@0/bus@42000000/sai@42660000";
		xcvr = "/soc@0/bus@42000000/xcvr@42680000";
		lpuart7 = "/soc@0/bus@42000000/serial@42690000";
		lpuart8 = "/soc@0/bus@42000000/serial@426a0000";
		lpi2c5 = "/soc@0/bus@42000000/i2c@426b0000";
		lpi2c6 = "/soc@0/bus@42000000/i2c@426c0000";
		lpi2c7 = "/soc@0/bus@42000000/i2c@426d0000";
		lpi2c8 = "/soc@0/bus@42000000/i2c@426e0000";
		lpspi5 = "/soc@0/bus@42000000/spi@426f0000";
		lpspi6 = "/soc@0/bus@42000000/spi@42700000";
		lpspi7 = "/soc@0/bus@42000000/spi@42710000";
		lpspi8 = "/soc@0/bus@42000000/spi@42720000";
		flexio1 = "/soc@0/bus@42000000/flexio@425c0000";
		flexio_i2c = "/soc@0/bus@42000000/flexio@425c0000/i2c-master";
		aips3 = "/soc@0/bus@42800000";
		usdhc1 = "/soc@0/bus@42800000/mmc@42850000";
		usdhc2 = "/soc@0/bus@42800000/mmc@42860000";
		fec = "/soc@0/bus@42800000/ethernet@42890000";
		eqos = "/soc@0/bus@42800000/ethernet@428a0000";
		usdhc3 = "/soc@0/bus@42800000/mmc@428b0000";
		epxp = "/soc@0/bus@42800000/epxp@4ae20000";
		cameradev = "/soc@0/bus@42800000/camera";
		isi_0 = "/soc@0/bus@42800000/camera/isi@4ae40000";
		mipi_csi = "/soc@0/bus@42800000/camera/csi@4ae00000";
		parallel_csi = "/soc@0/bus@42800000/camera/pcsi@4ac10070";
		gpio2 = "/soc@0/gpio@43810080";
		gpio3 = "/soc@0/gpio@43820080";
		gpio4 = "/soc@0/gpio@43830080";
		gpio1 = "/soc@0/gpio@47400080";
		ocotp = "/soc@0/efuse@47510000";
		imx93_uid = "/soc@0/efuse@47510000/soc-uid@c0";
		eth_mac1 = "/soc@0/efuse@47510000/mac-address@4ec";
		eth_mac2 = "/soc@0/efuse@47510000/mac-address@4f2";
		imx93_soc = "/soc@0/efuse@47510000/imx93-soc";
		s4muap = "/soc@0/mailbox@47520000";
		media_blk_ctrl = "/soc@0/system-controller@4ac10000";
		dphy = "/soc@0/system-controller@4ac10000/dphy";
		parallel_disp_fmt = "/soc@0/system-controller@4ac10000/dpi";
		dpi_to_lcdif = "/soc@0/system-controller@4ac10000/dpi/ports/port@0/endpoint";
		ldb = "/soc@0/ldb@4ac10020";
		ldb_ch0 = "/soc@0/ldb@4ac10020/lvds-channel@0/port@0/endpoint";
		ldb_phy = "/soc@0/phy@4ac10024";
		ldb_phy1 = "/soc@0/phy@4ac10024/port@0";
		ele_mu = "/soc@0/ele-mu";
		dsi = "/soc@0/dsi@4ae10000";
		dsi_to_lcdif = "/soc@0/dsi@4ae10000/ports/port@0/endpoint";
		lcdif = "/soc@0/lcd-controller@4ae30000";
		lcdif_disp = "/soc@0/lcd-controller@4ae30000/port";
		lcdif_to_dsi = "/soc@0/lcd-controller@4ae30000/port/endpoint@0";
		lcdif_to_ldb = "/soc@0/lcd-controller@4ae30000/port/endpoint@1";
		lcdif_to_dpi = "/soc@0/lcd-controller@4ae30000/port/endpoint@2";
		usbotg1 = "/soc@0/usb@4c100000";
		usbmisc1 = "/soc@0/usbmisc@4c100200";
		usbotg2 = "/soc@0/usb@4c200000";
		usbmisc2 = "/soc@0/usbmisc@4c200200";
		ddrmix_blk_ctrl = "/soc@0/blk-ctrl@4e010000";
		ddr = "/soc@0/memory-controller@4e300000";
		lpm = "/imx93-lpm";
		panel = "/lvds-panel";
		ele_reserved = "/reserved-memory/ele-reserved@a4120000";
		reg_vref_1v8 = "/regulator-adc-vref";
		reg_vdd_3v3 = "/regulator-3v3";
	};
};
